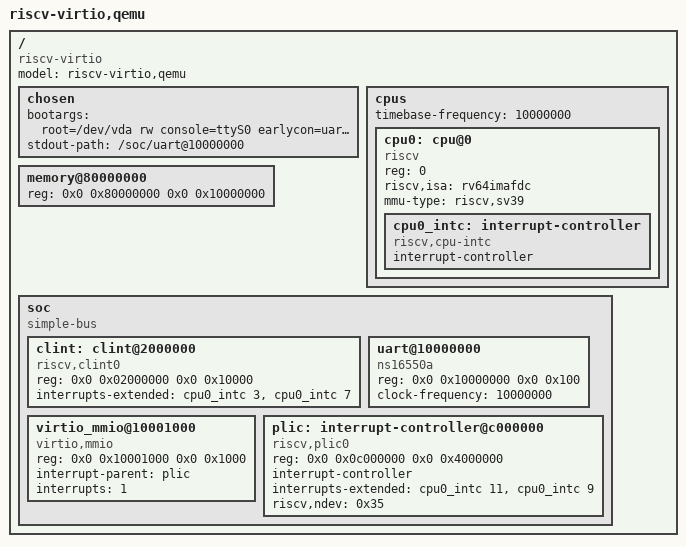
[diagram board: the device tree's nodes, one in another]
/dts-v1/;

/ {
    #address-cells = <2>;
    #size-cells = <2>;
    compatible = "riscv-virtio";
    model = "riscv-virtio,qemu";

    chosen {
        bootargs = "root=/dev/vda rw console=ttyS0 earlycon=uart8250,mmio,0x10000000 rootwait";
        stdout-path = "/soc/uart@10000000";
    };

    cpus {
        #address-cells = <1>;
        #size-cells = <0>;
        timebase-frequency = <10000000>;

        cpu0: cpu@0 {
            device_type = "cpu";
            reg = <0>;
            status = "okay";
            compatible = "riscv";
            riscv,isa = "rv64imafdc";
            mmu-type = "riscv,sv39";

            cpu0_intc: interrupt-controller {
                #interrupt-cells = <1>;
                interrupt-controller;
                compatible = "riscv,cpu-intc";
            };
        };
    };

    memory@80000000 {
        device_type = "memory";
        reg = <0x0 0x80000000 0x0 0x10000000>;
    };

    soc {
        #address-cells = <2>;
        #size-cells = <2>;
        compatible = "simple-bus";
        ranges;

        clint: clint@2000000 {
            compatible = "riscv,clint0";
            reg = <0x0 0x02000000 0x0 0x10000>;
            interrupts-extended = <&cpu0_intc 3>, <&cpu0_intc 7>;
        };

        uart@10000000 {
            compatible = "ns16550a";
            reg = <0x0 0x10000000 0x0 0x100>;
            clock-frequency = <10000000>;
            status = "okay";
        };

        virtio_mmio@10001000 {
            compatible = "virtio,mmio";
            reg = <0x0 0x10001000 0x0 0x1000>;
            interrupt-parent = <&plic>;
            interrupts = <1>;
        };

        plic: interrupt-controller@c000000 {
            compatible = "riscv,plic0";
            reg = <0x0 0x0c000000 0x0 0x4000000>;
            #interrupt-cells = <1>;
            interrupt-controller;
            interrupts-extended = <&cpu0_intc 11>, <&cpu0_intc 9>;
            riscv,ndev = <0x35>;
        };
    };
};
